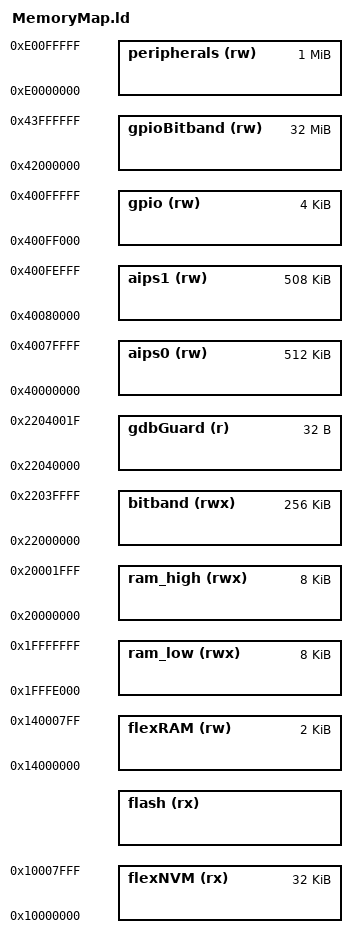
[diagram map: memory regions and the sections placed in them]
/* MemoryMap-mk.ld (180.ARM_Peripherals/Project_Settings/Linker_Files/)
 *
 */
 
/* ---- <<< Use Configuration Wizard in Context Menu >>> ---- */

/* <o> Stack Size
   <i> Required amount of stack space
   <i> In CMSIS this will determine the ISR stack size
   <0x0-0x40000:4>  <constant>
*/
__stack_size = 0x1000;

/* <o> Minimum Heap Size 
   <i> This is the minimum allocated.  
   <i> Available heap may be larger.
   <0x0-0x40000:4>  <constant>
*/
__heap_size  = 0x1000;

/* <o0> Bit-band / bit-manipulation-engine RAM size
   <i>  Space is allocated in SRAM_U memory region
   <i>  Each byte as also mapped to 8 words in .bitband memory region (if present)
   <i>
   <i>  C Example:
   <i>    // Variable allocated in bitband/bme accessible region (SRAM_U)
   <i>    // May be uint8_t, uint16_t or uint32_t
   <i>    __attribute__ ((section(".bitband_ram"))) uint32_t variable;
   <i>
   <i>    // Each word of array maps to an individual bit in bit-band
   <i>    __attribute__ ((section(".bitband"))) uint32_t variable_bits[8*sizeof(variable)];
   <i>
   <i>  See bme.h and bitband.h for more information
   <0x0-0x1000:4>  <constant>
*/
__sram_u_size = 0;
   
/*
 <e1> Enable Bootloader
 <i>  Enable custom USBDM bootloader  <constant>
*/
FORCE_BOOT_LOADER = DEFINED(bootloaderInformation) ? 1 : 0;
/*
    <o>  Bootloader size (usually 0x4000 if used) <constant>
    <i>  The bootloader is located at the bottom of the flash region
    <i>  This value is used to automatically adjust the available flash area 
 */
BOOT_LOADER_SIZE  = DEFINED(BOOT_LOADER_SIZE)  ? BOOT_LOADER_SIZE : 16384 * FORCE_BOOT_LOADER;
/* </e> */

/*
 * Memory Map generated by USBDM for MK20DX128M5
 */
 
MEMORY
{
  aips0          (rw)  : ORIGIN = 0x40000000, LENGTH = 0x00080000
  aips1          (rw)  : ORIGIN = 0x40080000, LENGTH = 0x0007F000
  gpio           (rw)  : ORIGIN = 0x400FF000, LENGTH = 0x00001000
  gpioBitband    (rw)  : ORIGIN = 0x42000000, LENGTH = 0x02000000
  peripherals    (rw)  : ORIGIN = 0xE0000000, LENGTH = 0x00100000
/*
    <o>  flexRAM address <constant>
    <o1> flexRAM size    <constant>
 */
  flexRAM        (rw)  : ORIGIN = 0x14000000, LENGTH = 0x00000800
/*
    <o>  Flex NVM address <constant>
    <o1> Flex NVM size    <constant>
 */
  flexNVM        (rx)  : ORIGIN = 0x10000000, LENGTH = 0x00008000
/*
    <o>  FLASH  address <constant>
    <o1> FLASH  size    <constant>
 */
  flash          (rx)  : ORIGIN = 0x00000000 + BOOT_LOADER_SIZE, LENGTH = 0x00020000 - BOOT_LOADER_SIZE
/*
    <o>  ram_high address <constant>
    <o1> ram_high size    <constant>
 */
  ram_high       (rwx) : ORIGIN = 0x20000000, LENGTH = 0x00002000
/*
    <o>  ram_low address <constant>
    <o1> ram_low size    <constant>
 */
  ram_low        (rwx) : ORIGIN = 0x1FFFE000, LENGTH = 0x00002000
/*
    <o>  bitband address <constant>
    <o1> bitband size    <constant>
 */
  bitband        (rwx) : ORIGIN = 0x22000000, LENGTH = 0x00040000
/*
 * Guard region above stack for GDB 
 */
  gdbGuard       (r)   : ORIGIN = 0x22040000, LENGTH = 0x00000020
};

REGION_ALIAS("ram","bitband");


/*
  <h> Section placement in Flash
  <i> Some Cortex-M4 Kinetis devices have additional Flash that may be used to hold code or constant data, or 
  <i> as backing storage for non-volatile memory (FlexRAM -> FlexNVM.)
  <i> These settings control which region (regular flash or FlexNVM) is used for various linker sections.
*/
/*  <s1>  Text (main code apart from reset)  <constant> text_rom      */
REGION_ALIAS("text_rom",         "flash");
/*  <s1>  Read-only data  <constant> data_rom      */
REGION_ALIAS("rodata_rom",       "flash");
/* </h> */
/*
  <h> Section placement in RAM
  <i> The RAM on Cortex-M4 Kinetis devices is divided into upper and lower memory regions.
  <i> These settings control which region is used for various linker sections.
  <i> These sections cannot cross regions as unaligned half-word and long-word accesses are not supported.
*/
/*  <s1>  Stack                              <constant> stack_ram      */
REGION_ALIAS("stack_ram",      "ram_high");
/*  <s1>  Heap                               <constant> heap_ram       */
REGION_ALIAS("heap_ram",       "ram_low");
/*  <s1>  Vector table relocated to RAM      <constant> interrupts_ram */
REGION_ALIAS("interrupts_ram", "ram_low");
/*  <s1>  Initialised DATA                   <constant>  data_ram      */
REGION_ALIAS("data_ram",       "ram_low");
/*  <s1>  Zeroed Data (BSS)                  <constant> bss_ram        */
REGION_ALIAS("bss_ram",        "ram_low");
/*  <s1>  Non-initialised DATA               <constant> noinit_ram     */
REGION_ALIAS("noinit_ram",     "ram_low");
/*  <s1>  Micro Trace Buffer                 <constant> mtb_ram        */
REGION_ALIAS("mtb_ram",        "ram_low");
/*  <s1>  USB Endpoint buffers               <constant> bdts_ram       */
REGION_ALIAS("bdts_ram",       "ram_low");
/*  <s1>  Bitband RAM - must be in ram_high  <constant> bdts_ram       */
REGION_ALIAS("bitband_ram",    "ram_high");
/* </h> */


INCLUDE Linker-rom.ld

